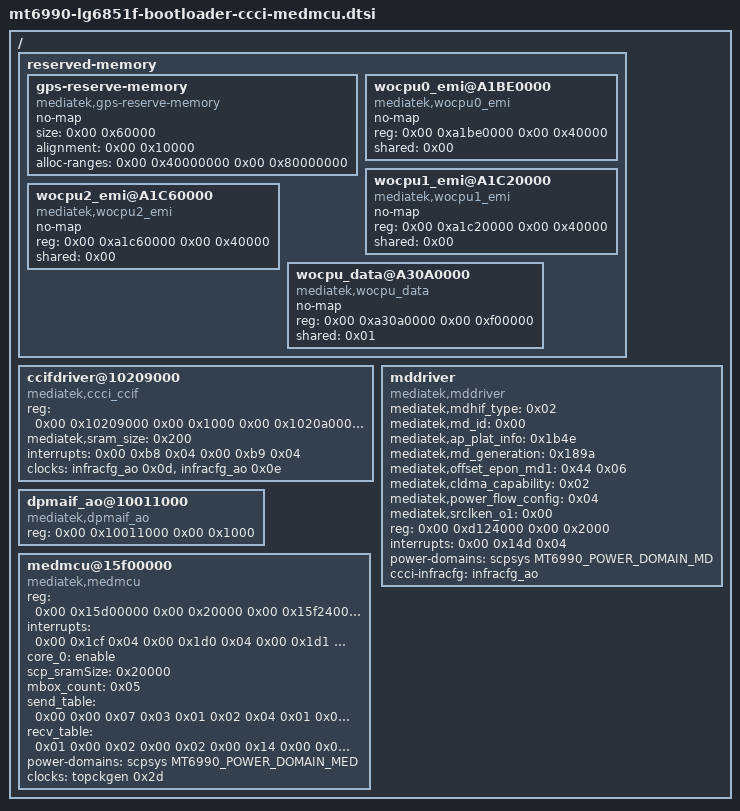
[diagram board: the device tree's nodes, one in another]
/*
 * Auto-generated by Stage6M v2 for LG6851F MT6990.
 * Imports only bootloader-required DT nodes from stock boot DTB.
 */

/ {
	/delete-node/ reserved-memory;
	/delete-node/ ccifdriver@10209000;
	/delete-node/ mddriver;
	/delete-node/ dpmaif_ao@10011000;
	/delete-node/ medmcu@15f00000;

	/* imported from stock DTS lines 504-550: reserved-memory */
		reserved-memory {
			#address-cells = <0x02>;
			#size-cells = <0x02>;
			ranges;

			gps-reserve-memory {
				compatible = "mediatek,gps-reserve-memory";
				no-map;
				size = <0x00 0x60000>;
				alignment = <0x00 0x10000>;
				alloc-ranges = <0x00 0x40000000 0x00 0x80000000>;
			};

			wocpu0_emi@A1BE0000 {
				compatible = "mediatek,wocpu0_emi";
				no-map;
				reg = <0x00 0xa1be0000 0x00 0x40000>;
				shared = <0x00>;
			};

			wocpu1_emi@A1C20000 {
				compatible = "mediatek,wocpu1_emi";
				no-map;
				reg = <0x00 0xa1c20000 0x00 0x40000>;
				shared = <0x00>;
			};

			wocpu2_emi@A1C60000 {
				compatible = "mediatek,wocpu2_emi";
				no-map;
				reg = <0x00 0xa1c60000 0x00 0x40000>;
				shared = <0x00>;
			};

			wocpu_data@A30A0000 {
				compatible = "mediatek,wocpu_data";
				no-map;
				reg = <0x00 0xa30a0000 0x00 0xf00000>;
				shared = <0x01>;
			};
		};

	/* imported from stock DTS lines 3785-3793: ccifdriver@10209000 */
		ccifdriver@10209000 {
			compatible = "mediatek,ccci_ccif";
			reg = <0x00 0x10209000 0x00 0x1000 0x00 0x1020a000 0x00 0x1000>;
			mediatek,sram_size = <0x200>;
			interrupts = <0x00 0xb8 0x04 0x00 0xb9 0x04>;
			clocks = <&infracfg_ao 0x0d>, <&infracfg_ao 0x0e>;
			clock-names = "infra-ccif0\0infra-ccif1";
		};

	/* imported from stock DTS lines 3795-3810: mddriver */
		mddriver {
			compatible = "mediatek,mddriver";
			mediatek,mdhif_type = <0x02>;
			mediatek,md_id = <0x00>;
			mediatek,ap_plat_info = <0x1b4e>;
			mediatek,md_generation = <0x189a>;
			mediatek,offset_epon_md1 = <0x44 0x06>;
			mediatek,cldma_capability = <0x02>;
			mediatek,power_flow_config = <0x04>;
			mediatek,srclken_o1 = <0x00>;
			reg = <0x00 0xd124000 0x00 0x2000>;
			interrupts = <0x00 0x14d 0x04>;
			power-domains = <&scpsys MT6990_POWER_DOMAIN_MD>;
			ccci-infracfg = <&infracfg_ao>;
		};

	/* imported from stock DTS lines 2760-2763: dpmaif_ao@10011000 */
		dpmaif_ao@10011000 {
			compatible = "mediatek,dpmaif_ao";
			reg = <0x00 0x10011000 0x00 0x1000>;
		};

	/* imported from stock DTS lines 3879-3895: medmcu@15f00000 */
		medmcu@15f00000 {
			compatible = "mediatek,medmcu";
			status = "okay";
			reg = <0x00 0x15d00000 0x00 0x20000 0x00 0x15f24000 0x00 0x1000 0x00 0x15f21000 0x00 0x1000 0x00 0x15f30000 0x00 0x1000 0x00 0x15f40000 0x00 0x1000 0x00 0x15f52000 0x00 0x1000 0x00 0x15f60000 0x00 0x40000 0x00 0x15fa5000 0x00 0x04 0x00 0x15ffb000 0x00 0x100 0x00 0x15ffb100 0x00 0x04 0x00 0x15ffb10c 0x00 0x04 0x00 0x15fa5020 0x00 0x04 0x00 0x15ffc000 0x00 0x100 0x00 0x15ffc100 0x00 0x04 0x00 0x15ffc10c 0x00 0x04 0x00 0x15fa5024 0x00 0x04 0x00 0x15ffd000 0x00 0x100 0x00 0x15ffd100 0x00 0x04 0x00 0x15ffd10c 0x00 0x04 0x00 0x15fa5028 0x00 0x04 0x00 0x15ffe000 0x00 0x100 0x00 0x15ffe100 0x00 0x04 0x00 0x15ffe10c 0x00 0x04 0x00 0x15fa502c 0x00 0x04 0x00 0x15fff000 0x00 0x100 0x00 0x15fff100 0x00 0x04 0x00 0x15fff10c 0x00 0x04 0x00 0x15fa5030 0x00 0x04 0x00 0x15b80000 0x00 0x100>;
			reg-names = "scp_sram_base\0scp_cfgreg\0scp_clkreg\0scp_cfgreg_core0\0scp_cfgreg_core1\0scp_bus_tracker\0scp_l1creg\0scp_cfgreg_sec\0mbox0_base\0mbox0_set\0mbox0_clr\0mbox0_init\0mbox1_base\0mbox1_set\0mbox1_clr\0mbox1_init\0mbox2_base\0mbox2_set\0mbox2_clr\0mbox2_init\0mbox3_base\0mbox3_set\0mbox3_clr\0mbox3_init\0mbox4_base\0mbox4_set\0mbox4_clr\0mbox4_init";
			interrupts = <0x00 0x1cf 0x04 0x00 0x1d0 0x04 0x00 0x1d1 0x04 0x00 0x1d2 0x04 0x00 0x1d3 0x04>;
			interrupt-names = "mbox0\0mbox1\0mbox2\0mbox3\0mbox4";
			core_0 = "enable";
			scp_sramSize = <0x20000>;
			mbox_count = <0x05>;
			send_table = <0x00 0x00 0x07 0x03 0x01 0x02 0x04 0x01 0x01 0x05 0x01 0x01 0x06 0x01 0x01 0x0b 0x02 0x12 0x0d 0x02 0x01 0x0f 0x03 0x01 0x10 0x03 0x01 0x11 0x03 0x01 0x12 0x03 0x01 0x13 0x03 0x01 0x14 0x03 0x01 0x15 0x03 0x01 0x16 0x03 0x02 0x17 0x03 0x02 0x18 0x03 0x02 0x1f 0x04 0x22>;
			recv_table = <0x01 0x00 0x02 0x00 0x02 0x00 0x14 0x00 0x07 0x01 0x02 0x00 0x08 0x01 0x0a 0x00 0x09 0x01 0x01 0x00 0x0a 0x01 0x02 0x00 0x05 0x01 0x01 0x01 0x0c 0x02 0x02 0x00 0x0e 0x02 0x02 0x00 0x19 0x03 0x02 0x00 0x1a 0x03 0x0a 0x00 0x1b 0x03 0x01 0x00 0x1c 0x03 0x05 0x00 0x1d 0x03 0x01 0x00 0x1e 0x03 0x02 0x00 0x11 0x03 0x01 0x01 0x20 0x04 0x1e 0x00>;
			power-domains = <&scpsys MT6990_POWER_DOMAIN_MED>;
			clocks = <&topckgen 0x2d>;
			clock-names = "medmcu_sel";
		};

};
